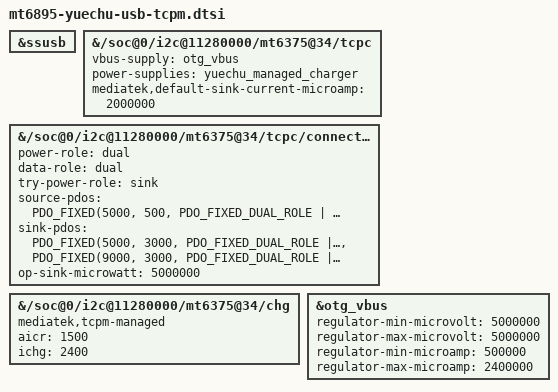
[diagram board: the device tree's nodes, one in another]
// SPDX-License-Identifier: GPL-2.0-only
/* Local OTG candidate: TCPM owns VBUS; MTU3 owns only the USB data role. */
&ssusb {
	/delete-property/ vbus-supply;
};

&{/soc@0/i2c@11280000/mt6375@34/tcpc} {
	vbus-supply = <&otg_vbus>;
	power-supplies = <&yuechu_managed_charger>;
	mediatek,default-sink-current-microamp = <2000000>;
};

&{/soc@0/i2c@11280000/mt6375@34/tcpc/connector} {
	power-role = "dual";
	data-role = "dual";
	try-power-role = "sink";
	source-pdos = <PDO_FIXED(5000, 500, PDO_FIXED_DUAL_ROLE |
				PDO_FIXED_DATA_SWAP | PDO_FIXED_USB_COMM)>;
	sink-pdos = <PDO_FIXED(5000, 3000, PDO_FIXED_DUAL_ROLE |
			      PDO_FIXED_DATA_SWAP | PDO_FIXED_USB_COMM)>,
		     <PDO_FIXED(9000, 3000, PDO_FIXED_DUAL_ROLE |
			      PDO_FIXED_DATA_SWAP | PDO_FIXED_USB_COMM)>;
	/*
	 * Low sink operating power so the CP manager may request small PPS
	 * currents during bring-up.  tcpm_pd_select_pdo() does not use this,
	 * so fixed-PDO selection (9 V/3 A) is unchanged.
	 */
	op-sink-microwatt = <5000000>;
};

yuechu_managed_charger: &{/soc@0/i2c@11280000/mt6375@34/chg} {
	mediatek,tcpm-managed;
	/*
	 * MT6375 input current limit for 5 V direct charging (the fallback path), in mA.
	 *
	 * This used to be 100: it was both the DT's initial CHG_AICR value and exactly the
	 * threshold at which mt6375_tcpm_apply_sink() enables the sink
	 * (sink_limit_ua >= MT6375_TCPM_SINK_ENABLE_UA == 100000 uA),
	 * so without PPS the sink is only enabled at the threshold: input held at 100 mA,
	 * while the phone itself needs ~450 mA - plugged in, the battery still net-discharges (measured -452 mA).
	 * 1500 mA matches the upper limit the tcpm glue accepts and lets the 5 V path charge properly.
	 */
	aicr = <1500>;
	/* Android-like 10 W battery-side cap for the 9 V direct path. */
	ichg = <2400>;
};

&otg_vbus {
	regulator-min-microvolt = <5000000>;
	regulator-max-microvolt = <5000000>;
	regulator-min-microamp = <500000>;
	regulator-max-microamp = <2400000>;
};
